# apollo510 register map
Vendor: Ambiq Micro; Series: Apollo; File version: 1.0
CPU: CM55 r1p1, little endian, MPU, FPU, double-precision FPU, DSP, I-cache, D-cache, VTOR, ITCM, DTCM, 4 interrupt priority bits, 0 interrupts, 8 SAU regions
Registers are 32-bit, read-write, reset 0x0 unless marked. A register's access mark holds for its fields unless they carry their own. Offsets are from the block's base; [hi:lo] are bit positions; {n}, {i} and the like mark numbered series; 'fields as' and 'values as' point back to an identical list.

## SDIO0 (part 2 of 2) — SDIO Control Registers
Base 0x40070000
Same registers: SDIO1 0x40071000
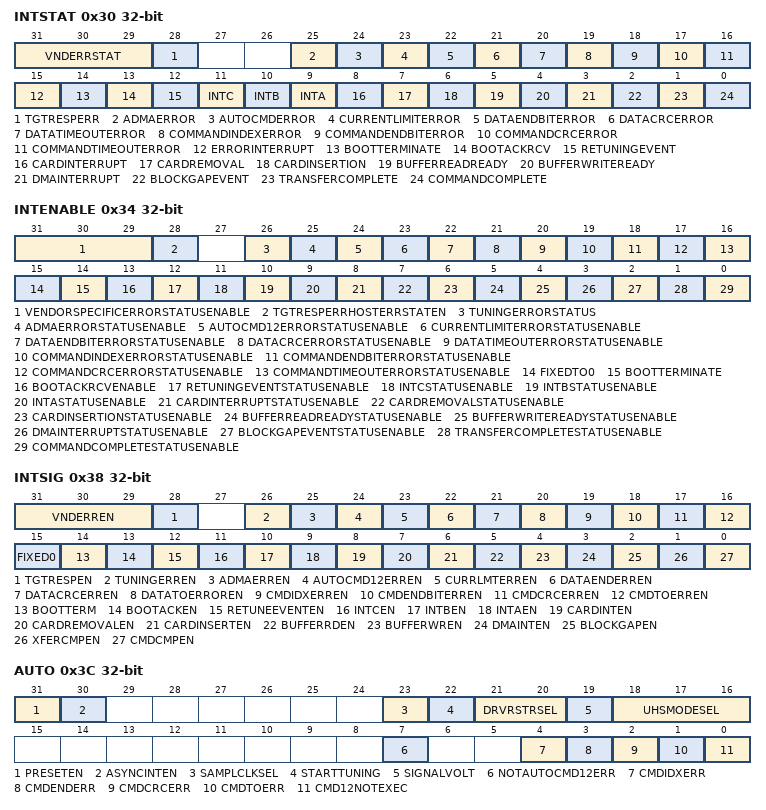
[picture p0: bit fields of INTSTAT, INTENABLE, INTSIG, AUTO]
0x30 INTSTAT — Interrupt enable
  [31:29] VNDERRSTAT — Vendor specific error status.
    1=READY; 0=NOTREADY
  [28] TGTRESPERR — Occurs when detecting error in aximst_bresp or aximst_rresp
    0=NOERROR; 1=ERROR
  [25] ADMAERROR — This bit is set when the Host Controller detects errors during ADMA based data transfer. The state of the ADMA at an error occurrence is saved in the ADMA Error Status Register.
    1=ERROR; 0=NOERROR
  [24] AUTOCMDERROR — Auto CMD12 and Auto CMD23 use this error status. This bit is set when detecting that one of the bits D00-D04 in Auto CMD Error Status register has changed from 0 to 1. In case of Auto CMD12, this bit is set to 1, not only when the errors in Auto CMD12 occur but also when Auto CMD12 is not executed due to the previous command error.
    0=NOERROR; 1=ERROR
  [23] CURRENTLIMITERROR — By setting the SD Bus Power bit in the Power Control Register, the HC is requested to supply power for the SD Bus. If the HC supports the Current Limit Function, it can be protected from an Illegal card by stopping power supply to the card in which case this bit indicates a failure status. Reading 1 means the HC is not supplying power to SD card due to some failure. Reading 0 means that the HC is supplying power and no error has occurred. This bit shall always set to be 0, if the HC does not support this function.
    0=NOERROR; 1=ERROR (Power Fail)
  [22] DATAENDBITERROR — Occurs when detecting 0 at the end bit position of read data which uses the DAT line or the end bit position of the CRC status.
    0=NOERROR; 1=ERROR
  [21] DATACRCERROR — Occurs when detecting CRC error when transferring read data which uses the DAT line or when detecting the Write CRC Status having a value of other than 0.
    0=NOERROR; 1=ERROR
  [20] DATATIMEOUTERROR — Occurs when detecting one of following timeout conditions. 1. Busy Timeout for R1b, R5b type. 2. Busy Timeout after Write CRC status 3. Write CRC status Timeout 4. Read Data Timeout
    0=NOERROR; 1=ERROR (Timeout)
  [19] COMMANDINDEXERROR — Occurs if a Command Index error occurs in the Command Response.
    0=NOERROR; 1=ERROR
  [18] COMMANDENDBITERROR — Occurs only if the no response is returned within 64 SDCLK cycles from the end bit of the command. If the HC detects a CMD line conflict, in which case Command CRC Error shall also be set. This bit shall be set without waiting for 64 SDCLK cycles because the command will be aborted by the HC.
    0=NOERROR; 1=ERROR (Timeout)
  [17] COMMANDCRCERROR — Occurs when detecting that the end bit of a command response is 0.
    0=NOERROR; 1=ERROR (End Bit Error Generated)
  [16] COMMANDTIMEOUTERROR — Command CRC Error is generated in two cases. 1. If a response is returned and the Command Time-out Error is set to 0, this bit is set to 1 when detecting a CRT error in the command response 2. The HC detects a CMD line conflict by monitoring the CMD line when a command is issued. If the HC drives the CMD line to 1 level, but detects 0 level on the CMD line at the next SDCLK edge, then the HC shall abort the command (Stop driving CMD line) and set this bit to 1. The Command Timeout Error shall also be set to 1 to distinguish CMD line conflict.
    0=NOERROR; 1=ERROR (CRC Error Generated)
  [15] ERRORINTERRUPT — If any of the bits in the Error Interrupt Status Register are set, then this bit is set. Therefore the HD can test for an error by checking this bit first.
    0=NOERROR; 1=ERROR
  [14] BOOTTERMINATE — Interrupt This status is set if the boot operation get terminated
    0=OK (Boot operation is not terminated.); 1=BOOTTERM (Boot operation is terminated)
  [13] BOOTACKRCV — This status is set if the boot acknowledge is received from device.
    0=NOACK (Boot ack is not received.); 1=ACK (Boot ack is received.)
  [12] RETUNINGEVENT — This status is set if Re-Tuning Request in the Present State register changes from 0 to 1. Host Controller requests Host Driver to perform re-tuning for next data transfer. Current data transfer (not large block count) can be completed without re-tuning.
    1=RETUNE (ReTuning should be performed); 0=NORETUNE (ReTuning is not required)
  [11] INTC — This status is set if INT_C is enabled and INT_C# pin is in low level. Writing this bit to 1 does not clear this bit. It is cleared by resetting the INT_C interrupt factor
  [10] INTB — This status is set if INT_B is enabled and INT_B# pin is in low level. Writing this bit to 1 does not clear this bit. It is cleared by resetting the INT_B interrupt factor
  [9] INTA — This status is set if INT_A is enabled and INT_A# pin is in low level. Writing this bit to 1 does not clear this bit. It is cleared by resetting the INT_A interrupt factor
  [8] CARDINTERRUPT — Writing this bit to 1 does not clear this bit. It is cleared by resetting the SD card interrupt factor. In 1-bit mode, the HC shall detect the Card Interrupt without SD Clock to support wakeup. In 4-bit mode, the card interrupt signal is sampled during the interrupt cycle, so there are some sample delays between the interrupt signal from the card and the interrupt to the Host system. when this status has been set and the HD needs to start this interrupt service, Card Interrupt Status Enable in the Normal Interrupt Status register shall be set to 0 in order to clear the card interrupt statuses latched in the HC and stop driving the Host System. After completion of the card interrupt service (the reset factor in the SD card and the interrupt signal may not be asserted), set Card Interrupt Status Enable to 1 and start sampling the interrupt signal again. Interrupt detected by DAT[1] is supported when there is a card per slot. In case of shared bus, interrupt pins are used to detect interrupts. If 000b is set to Interrupt Pin Select in the Shared Bus Control register, this status is effective. Non-zero value is set to Interrupt Pin Select, INT_A, INT_B or INT_C is then used to device interrupts.
    0=NOINT (No Card Interrupt); 1=INT (Generate Card Interrupt)
  [7] CARDREMOVAL — This status is set if the Card Inserted in the Present State register changes from 1 to 0. When the HD writes this bit to 1 to clear this status the status of the Card Inserted in the Present State register should be confirmed. Because the card detect may possibly be changed when the HD clear this bit an Interrupt event may not be generated.
    0=STABLE (Card State Stable or Debouncing); 1=REMOVED (Card Removed)
  [6] CARDINSERTION — This status is set if the Card Inserted in the Present State register changes from 0 to 1. When the HD writes this bit to 1 to clear this status the status of the Card Inserted in the Present State register should be confirmed. Because the card detect may possibly be changed when the HD clear this bit an Interrupt event may not be generated.
    0=STABLE (Card State Stable or Debouncing); 1=INSERTED (Card Inserted)
  [5] BUFFERREADREADY — This status is set if the Buffer Read Enable changes from 0 to 1. Buffer Read Ready is set to 1 for every CMD19 execution in tuning procedure.
    0=NOREADY (Not Ready to read Buffer.); 1=READY (Ready to read Buffer.)
  [4] BUFFERWRITEREADY — This status is set if the Buffer Write Enable changes from 0 to 1.
    0=NOTREADY (Not Ready to Write Buffer.); 1=READY (Ready to Write Buffer.)
  [3] DMAINTERRUPT — This status is set if the HC detects the Host DMA Buffer Boundary in the Block Size regiser.
    0=NOINT (No DMA Interrupt); 1=INT (DMA Interrupt is Generated)
  [2] BLOCKGAPEVENT — If the Stop At Block Gap Request in the Block Gap Control Register is set, this bit is set. Read Transaction: This bit is set at the falling edge of the DAT Line Active Status (When the transaction is stopped at SD Bus timing. The Read Wait must be supported inorder to use this function). Write Transaction: This bit is set at the falling edge of Write Transfer Active Status (After getting CRC status at SD Bus timing).
    0=NOEVENT (No Block Gap Event); 1=STOPPED (Transaction stopped at Block Gap)
  [1] TRANSFERCOMPLETE — This bit is set when a read / write transaction is completed. Read Transaction: This bit is set at the falling edge of Read Transfer Active Status. There are two cases in which the Interrupt is generated. The first is when a data transfer is completed as specified by data length (After the last data has been read to the Host System). The second is when data has stopped at the block gap and completed the data transfer by setting the Stop At Block Gap Request in the Block Gap Control Register (After valid data has been read to the Host System). Write Transaction: This bit is set at the falling edge of the DAT Line Active Status. There are two cases in which the Interrupt is generated. The first is when the last data is written to the card as specified by data length and Busy signal is released. The second is when data transfers are stopped at the block gap by setting Stop At Block Gap Request in the Block Gap Control Register and data transfers completed. (After valid data is written to the SD card and the busy signal is released). Note: Transfer Complete has higher priority than Data Time-out Error. If both bits are set to 1, the data transfer can be considered complete Note: While performing tuning procedure (Execute Tuning is set to 1), Transfer Complete is not set to 1
    0=NODATA (No Data Transfer Complete); 1=COMPLETE (Data Transfer Complete)
  [0] COMMANDCOMPLETE — This bit is set when we get the end bit of the command response (Except Auto CMD12 and Auto CMD23) Note: Command Time-out Error has higher priority than Command Complete. If both are set to 1, it can be considered that the response was not received correctly.
    0=NOCMP (No Command Complete); 1=CMDCMP (Command Complete)
0x34 INTENABLE — Normal interrupt status enable
  [31:29] VENDORSPECIFICERRORSTATUSENABLE
  [28] TGTRESPERRHOSTERRSTATEN
  [26] TUNINGERRORSTATUS — enable
  [25] ADMAERRORSTATUSENABLE
  [24] AUTOCMD12ERRORSTATUSENABLE
  [23] CURRENTLIMITERRORSTATUSENABLE
  [22] DATAENDBITERRORSTATUSENABLE
  [21] DATACRCERRORSTATUSENABLE
  [20] DATATIMEOUTERRORSTATUSENABLE
  [19] COMMANDINDEXERRORSTATUSENABLE
  [18] COMMANDENDBITERRORSTATUSENABLE
  [17] COMMANDCRCERRORSTATUSENABLE
  [16] COMMANDTIMEOUTERRORSTATUSENABLE
  [15] FIXEDTO0 — The HC shall control error Interrupts using the Error Interrupt Status Enable register.
  [14] BOOTTERMINATE — Boot is terminated?
  [13] BOOTACKRCVENABLE — Interrupt
  [12] RETUNINGEVENTSTATUSENABLE — Interrupt
  [11] INTCSTATUSENABLE — If this bit is set to 0, the Host Controller shall clear the interrupt request to the System. The Host Driver may clear this bit before servicing the INT_C and may set this bit again after all interrupt requests to INT_C pin are cleared to prevent inadvertent interrupts. Interrupt enable
  [10] INTBSTATUSENABLE — If this bit is set to 0, the Host Controller shall clear the interrupt request to the System. The Host Driver may clear this bit before servicing the INT_B and may set this bit again after all interrupt requests to INT_B pin are cleared to prevent inadvertent interrupts.
  [9] INTASTATUSENABLE — If this bit is set to 0, the Host Controller shall clear the interrupt request to the System. The Host Driver may clear this bit before servicing the INT_A and may set this bit again after all interrupt requests to INT_A pin are cleared to prevent inadvertent interrupts.
  [8] CARDINTERRUPTSTATUSENABLE — If this bit is set to 0, the HC shall clear Interrupt request to the System. The Card Interrupt detection is stopped when this bit is cleared and restarted when this bit is set to 1. The HD may clear the Card Interrupt Status Enable before servicing the Card Interrupt and may set this bit again after all Interrupt requests from the card are cleared to prevent inadvertent Interrupts.
  [7] CARDREMOVALSTATUSENABLE — Description
  [6] CARDINSERTIONSTATUSENABLE — Description
  [5] BUFFERREADREADYSTATUSENABLE — Description
  [4] BUFFERWRITEREADYSTATUSENABLE — Description
  [3] DMAINTERRUPTSTATUSENABLE — Description
  [2] BLOCKGAPEVENTSTATUSENABLE — Description
  [1] TRANSFERCOMPLETESTATUSENABLE — Description
  [0] COMMANDCOMPLETESTATUSENABLE — Description
0x38 INTSIG — Normal interrupt signal enable
  [31:29] VNDERREN — FIXME - Bitfield description needed here.
  [28] TGTRESPEN — Interrupt
    0=MASKED; 1=ENABLED
  [26] TUNINGERREN
    0=MASKED; 1=ENABLED
  [25] ADMAERREN
    0=MASKED; 1=ENABLED
  [24] AUTOCMD12ERREN
    0=MASKED; 1=ENABLED
  [23] CURRLMTERREN
    0=MASKED; 1=ENABLED
  [22] DATAENDERREN
    0=MASKED; 1=ENABLED
  [21] DATACRCERREN
    0=MASKED; 1=ENABLED
  [20] DATATOERROREN
    0=MASKED; 1=ENABLED
  [19] CMDIDXERREN
    0=MASKED; 1=ENABLED
  [18] CMDENDBITERREN
    0=MASKED; 1=ENABLED
  [17] CMDCRCERREN
    0=MASKED; 1=ENABLED
  [16] CMDTOERREN
    0=MASKED; 1=ENABLED
  [15] FIXED0 — Fixed to 0. The HD shall control error Interrupts using the Error Interrupt Signal Enable register.
    0=MASKED; 1=ENABLED
  [14] BOOTTERM — Boot terminate interrupt signal enable
    0=MASKED; 1=ENABLED
  [13] BOOTACKEN — Interrupt
    0=MASKED; 1=ENABLED
  [12] RETUNEEVENTEN — Interrupt signal enable
    0=MASKED; 1=ENABLED
  [11] INTCEN — Interrupt
    0=MASKED; 1=ENABLED
  [10] INTBEN — Interrupt
    0=MASKED; 1=ENABLED
  [9] INTAEN — Interrupt
    0=MASKED; 1=ENABLED
  [8] CARDINTEN — Interrupt
    0=MASKED; 1=ENABLED
  [7] CARDREMOVALEN — Interrupt
    0=MASKED; 1=ENABLED
  [6] CARDINSERTEN — Interrupt
    0=MASKED; 1=ENABLED
  [5] BUFFERRDEN — Interrupt
    0=MASKED; 1=ENABLED
  [4] BUFFERWREN — Interrupt
    0=MASKED; 1=ENABLED
  [3] DMAINTEN — Interrupt
    0=MASKED; 1=ENABLED
  [2] BLOCKGAPEN — Interrupt
    0=MASKED; 1=ENABLED
  [1] XFERCMPEN — Interrupt
    0=MASKED; 1=ENABLED
  [0] CMDCMPEN — Interrupt
    0=MASKED; 1=ENABLED
0x3C AUTO — Auto CMD error status
  [31] PRESETEN — Host Controller Version 3.00 supports this bit. As the operating SDCLK frequency and I/O driver strength depend on the Host System implementation, it is difficult to determine these parameters in the Standard Host Driver. When Preset Value Enable is set to automatic. This bit enables the functions defined in the Preset Value registers. If this bit is set to 0, SDCLK Frequency Select, Clock Generator Select in the Clock Control register and Driver Strength Select in Host Control 2 register are set by Host Driver. If this bit is set to 1, SDCLK Frequency Select, Clock Generator Select in the Clock Control register and Driver Strength Select in Host Control 2 register are set by Host Controller as specified in the Preset Value registers.
    1=AUTOEN (Automatic Selection by Preset Value are Enabled); 0=HOSTCTRL (SDCLK and Driver Strength are controlled by Host Driver)
  [30] ASYNCINTEN — This bit can be set to 1 if a card support asynchronous interrupt and Asynchronous Interrupt Support is set to 1 in the Capabilities register. Asynchronous interrupt is effective when DAT[1] interrupt is used in 4-bit SD mode (and zero is set to Interrupt Pin Select in the Shared Bus Control register). If this bit is set to 1, the Host Driver can stop the SDCLK during asynchronous interrupt period to save power. During this period, the Host Controller continues to deliver Card Interrupt to the host when it is asserted by the Card.
    1=ENABLED; 0=DISABLED
  [23] SAMPLCLKSEL — This bit is set by tuning procedure when Execute Tuning is cleared. Writing 1 to this bit is meaningless and ignored. Setting 1 means that tuning is completed successfully and setting 0 means that tuning is failed. Host Controller uses this bit to select sampling clock to receive CMD and DAT. This bit is cleared by writing 0. Change of this bit is not allowed while the Host Controller is receiving response or a read data block.
    1=TUNEDCLK (Tuned clock is used to sample data); 0=FIXEDCLK (Fixed clock is used to sample data)
  [22] STARTTUNING — This bit is set to 1 to start tuning procedure and automatically cleared when tuning procedure is completed. The result of tuning is indicated to Sampling Clock Select. Tuning procedure is aborted by writing 0 for more detail about tuning procedure.
    1=TUNESTART (Execute Tuning,); 0=TUNECMP (Not Tuned or Tuning Completed)
  [21:20] DRVRSTRSEL — Host Controller output driver in 1.8V signaling is selected by this bit. In 3.3V signaling, this field is not effective. This field can be set depends on Driver Type A, C and D support bits in the Capabilities register. This bit depends on setting of Preset Value Enable. If Preset Value Enable = 0, this field is set by Host Driver. If Preset Value Enable = 1, this field is automatically set by a value specified in the one of Preset Value registers.
    0=DRVRB (Driver Type B is Selected (Default)); 1=DRVRA (Driver Type A is Selected); 2=DRVRC (Driver Type C is Selected); 3=DRVRD (Driver Type D is Selected)
  [19] SIGNALVOLT — This bit controls voltage regulator for I/O cell. 3.3V is supplied to the card regardless of signaling voltage. Setting this bit from 0 to 1 starts changing signal voltage from 3.3V to 1.8V. 1.8V regulator output shall be stable within 5ms. Host Controller clears this bit if switching to 1.8V signaling fails. Clearing this bit from 1 to 0 starts changing signal voltage from 1.8V to 3.3V. 3.3V regulator output shall be stable within 5ms. Host Driver can set this bit to 1 when Host Controller supports 1.8V signaling (One of support bits is set to 1: SDR50, SDR104 or DDR50 in the Capabilities register) and the card or device supports UHS-I
    1=1_8V (1.8V Signaling); 0=3_3V (3.3V Signaling)
  [18:16] UHSMODESEL — This field is used to select one of UHS-I modes and effective when 1.8V Signaling Enable is set to 1. If Preset Value Enable in the Host Control 2 register is set to 1, Host Controller sets SDCLK Frequency Select, Clock Generator Select in the Clock Control register and Driver Strength Select according to Preset Value registers. In this case, one of preset value registers is selected by this field. Host Driver needs to reset SD Clock Enable before changing this field to avoid generating clock glitch. After setting this field, Host Driver sets SD Clock Enable again. When SDR50, SDR104 or DDR50 is selected for SDIO card, interrupt detection at the block gap shall not be used. Read Wait timing is changed for these modes. Refer to the SDIO Specification Version 3.00 for more detail.
    0=SDR12 (UHS-I mode SDR12); 1=SDR25 (UHS-I mode SDR25); 2=SDR50 (UHS-I mode SDR50); 3=SDR104 (UHS-I mode SDR104); 4=DDR50 (UHS-I mode DDR50)
  [7] NOTAUTOCMD12ERR — Setting this bit to 1 means CMD_wo_DAT is not executed due to an Auto CMD12 error (D04 - D01) in this register. This bit is set to 0 when Auto CMD Error is generated by Auto CMD23
    0=NOERROR; 1=ERROR (Not Issued)
  [4] CMDIDXERR — Occurs if the Command Index error occurs in response to a command.
    0=NOERROR; 1=ERROR
  [3] CMDENDERR — Occurs when detecting that the end bit of command response is 0.
    0=NOERROR; 1=ERROR (End Bit Error Generated)
  [2] CMDCRCERR — Occurs when detecting a CRC error in the command response.
    0=NOERROR; 1=ERROR (CRC Error Generated)
  [1] CMDTOERR — Occurs if the no response is returned within 64 SDCLK cycles from the end bit of the command. If this bit is set to 1, the other error status bits (D04 - D02) are meaningless.
    0=NOERROR; 1=ERROR (Timeout)
  [0] CMD12NOTEXEC — If memory multiple block data transfer is not started due to command error, this bit is not set because it is not necessary to issue Auto CMD12. Setting this bit to 1 means the HC cannot issue Auto CMD12 to stop memory multiple block transfer due to some error. If this bit is set to 1, other error status bits (D04 - D01) are meaningless. This bit is set to 0 when Auto CMD Error is generated by Auto CMD23
    0=EXECUTED; 1=NOTEXECUTED
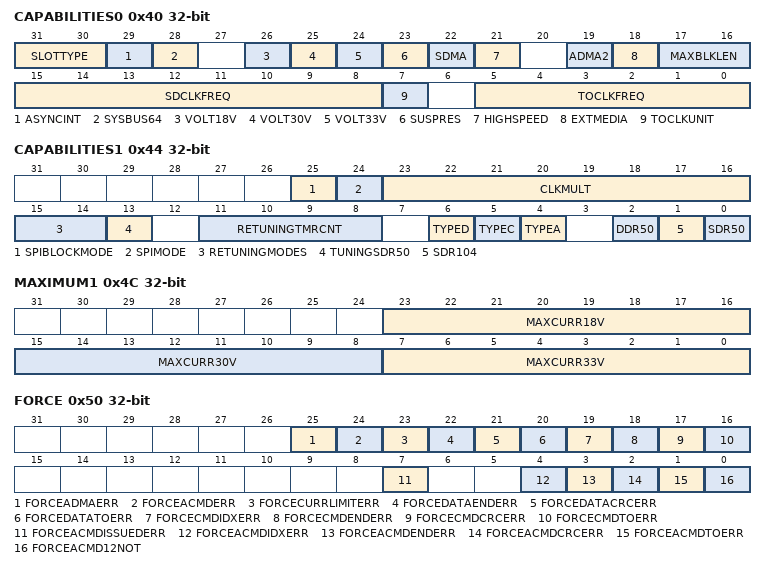
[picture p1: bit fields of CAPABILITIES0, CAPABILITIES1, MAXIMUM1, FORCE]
0x40 CAPABILITIES0 — Capabilities
  [31:30] SLOTTYPE — This field indicates usage of a slot by a specific Host System. (A host controller register set is defined per slot.) Embedded slot for one device (01b) means that only one non-removable device is connected to a SD bus slot. Shared Bus Slot (10b) can be set if Host Controller supports Shared Bus Control register. The Standard Host Driver controls only a removable card or one embedded device is connected to a SD bus slot. If a slot is configured for shared bus (10b), the Standard Host Driver does not control embedded devices connected to a shared bus. Shared bus slot is controlled by a specific host driver developed by a Host System.
    0=REMOVABLE (Removable card slot); 1=EMBEDDED (Embedded Slot for One Device); 2=SHARED (Shared Bus Slot)
  [29] ASYNCINT — Refer to SDIO Specification Version 3.00 about asynchronous interrupt.
    1=SUPPORTED (Asynchronous Interrupt Supported); 0=NOTSUPPORTED (Asynchronous Interrupt Not Supported)
  [28] SYSBUS64
    1=SUPPORTED (Supports 64 bit system address); 0=NOTSUPPORTED (Does not support 64 bit system address)
  [26] VOLT18V — Voltage support 1.8v
    0=NOTSUPPORTED (1.8 V Not Supported); 1=SUPPORTED (1.8 V Supported)
  [25] VOLT30V — Voltage support 3.0v
    0=NOTSUPPORTED (3.0 V Not Supported); 1=SUPPORTED (3.0 V Supported)
  [24] VOLT33V
    0=NOTSUPPORTED (3.3 V Not Supported); 1=SUPPORTED (3.3 V Supported)
  [23] SUSPRES — This bit indicates whether the HC supports Suspend / Resume functionality. If this bit is 0, the Suspend and Resume mechanism are not supported and the HD shall not issue either Suspend / Resume commands.
    0=NOTSUPPORTED (Suspend / Resume Not Supported); 1=SUPPORTED (Suspend / Resume Supported)
  [22] SDMA — This bit indicates whether the HC is capable of using DMA to transfer data between system memory and the HC directly.
    0=NOTSUPPORTED (SDMA Not Supported); 1=SUPPORTED (SDMA Supported.)
  [21] HIGHSPEED — This bit indicates whether the HC and the Host System support High Speed mode and they can supply SD Clock frequency from 25Mhz to 50 Mhz (for SD)/ 20MHz to 52MHz (for MMC).
    0=NOTSUPPORTED (High Speed Not Supported); 1=SUPPORTED (High Speed Supported)
  [19] ADMA2
    1=SUPPORTED (ADMA2 support.); 0=NOTSUPPORTED (ADMA2 not support)
  [18] EXTMEDIA — This bit indicates whether the Host Controller is capable of using 8-bit bus width mode. This bit is not effective when Slot Type is set to 10b. In this case, refer to Bus Width Preset in the Shared Bus resister. Supported
    1=SUPPORTED (Extended Media Bus Supported); 0=NOTSUPPORTED (Extended Media Bus not supported)
  [17:16] MAXBLKLEN — This value indicates the maximum block size that the HD can read and write to the buffer in the HC. The buffer shall transfer this block size without wait cycles. Three sizes can be defined as indicated below.
    0=512 byte; 1=1024 byte; 2=2048 byte; 3=4096 byte
  [15:8] SDCLKFREQ — 6-bit Base Clock Frequency This mode is supported by the Host Controller Version 1.00 and 2.00. Upper 2-bit is not effective and always 0. Unit values are 1MHz. The supported clock range is 10MHz to 63MHz. 11xx xxxxb Not supported 0011 1111b 63MHz 0000 0010b 2MHz 0000 0001b 1MHz 0000 0000b Get information via another method (2) 8-bit Base Clock Frequency This mode is supported by the Host Controller Version 3.00.Unit values are 1MHz. The supported clock range is 10MHz to 255MHz. FFh 255MHz 02h 2MHz 01h 1MHz 00h Get information via another method If the real frequency is 16.5MHz, the lager value shall be set 0001 0001b (17MHz) because the Host Driver use this value to calculate the clock divider value (Refer to the SDCLK Frequency Select in the Clock Control register.) and it shall not exceed upper limit of the SD Clock frequency. If these bits are all 0, the Host System has to get information via another method. Some example frequency values are enumerated below.
    255=255MHZ (2) 8-bit base clock frequency supports frequencies 10MHz-255MHz.); 63=63MHZ (1) 6-bit base clock frequency supports frequencies 10MHz-63MHz. 2) 8-bit base clock frequency supports frequencies 10MHz-255MHz.); 2=2MHZ (1) 6-bit base clock frequency supports frequencies 10MHz-63MHz. 2) 8-bit base clock frequency supports frequencies 10MHz-255MHz.); 1=1MHZ (1) 6-bit base clock frequency supports frequencies 10MHz-63MHz. 2) 8-bit base clock frequency supports frequencies 10MHz-255MHz.); 0=OTHER (Get information via another method)
  [7] TOCLKUNIT — This bit shows the unit of base clock frequency used to detect Data Timeout Error.
    0=KHZ; 1=MHZ
  [5:0] TOCLKFREQ — This bit shows the base clock frequency used to detect Data Timeout Error. Not 0 - 1Khz to 63Khz or 1Mhz to 63Mhz Note: The Host System shall support at least one of these voltages above. The HD sets the SD Bus Voltage Select in Power Control register according to these support bits. If multiple voltages are supported, select the usable lower voltage by comparing the OCR value from the card. These registers indicate maximum current capability for each voltage. The value is meaningful if Voltage Support is set in the Capabilities register.
    1=1KHZMHZ (1KHZ or 1MHZ); 2=2KHZMHZ (2KHZ or 2MHZ); 63=63KHZMHZ (63KHZ or 63MHZ); 0=OTHER (Get Information via another method.)
0x44 CAPABILITIES1 — Capabilities
  [25] SPIBLOCKMODE
    0=NOTSUPPORTED; 1=SUPPORTED
  [24] SPIMODE
    0=NOTSUPPORTED; 1=SUPPORTED
  [23:16] CLKMULT — This field indicates clock multiplier value of programmable clock generator. Refer to Clock Control register. Setting 00h means that Host Controller does not support programmable clock generator. The multiplier is (CLKMULT+1).
    255=MULTX256 (Clock Multiplier M = 256); 2=MULTX3 (Clock Multiplier M = 3); 1=MULTX2 (Clock Multiplier M = 2); 0=NOTSUPPORTED (Clock Multiplier is Not Supported)
  [15:14] RETUNINGMODES — This field defines the re-tuning capability of a Host Controller and how to manage the data transfer length and a Re-Tuning Timer by the Host Driver There are two re-tuning timings: Re-Tuning Request and expiration of a Re-Tuning Timer. By receiving either timing, the Host Driver executes the re-tuning procedure just before a next command issue
    0=MODE1; 1=MODE2; 2=MODE3; 3=NOTSUPPORTED (Clock Multiplier is not supported.)
  [13] TUNINGSDR50 — If this bit is set to 1, this Host Controller requires tuning to operate SDR50. (Tuning is always required to operate SDR104.)
    1=TUNINGREQD (SDR50 requires tuning); 0=NOTUNINGREQD (SDR50 does not require tuning)
  [11:8] RETUNINGTMRCNT — This field indicates an initial value of the Re-Tuning Timer for Re-Tuning Mode 1 to 3. 0h - Get information via other source.
    0=OTHER (0h Get information via other source.); 1=1SEC (1 seconds); 2=2SEC (2 seconds); 3=4SEC (4 seconds); 4=8S (8 seconds); 5=16S (16 seconds); 6=32S (32 seconds); 7=64S (64 seconds); 8=128S (128 seconds); 9=256S (256 seconds); 10=512S (512 seconds); 11=1024S (1024 seconds)
  [6] TYPED — Reserved This bit indicates support of Driver Type D for 1.8 Signaling.
    1=SUPPORTED (Driver Type D is Supported); 0=NOTSUPPORTED (Driver Type D is Not Supported)
  [5] TYPEC — This bit indicates support of Driver Type C for 1.8 Signaling.
    1=SUPPORTED (Driver Type C is Supported); 0=NOTSUPPORTED (Driver Type C is Not Supported)
  [4] TYPEA — This bit indicates support of Driver Type A for 1.8 Signaling.
    1=SUPPORTED (Driver Type A is Supported); 0=NOTSUPPORTED (Driver Type A is Not Supported)
  [2] DDR50 — FIXME - Bitfield description needed here.
    1=SUPPORTED (DDR50 is Supported); 0=NOTSUPPORTED (DDR50 is Not Supported)
  [1] SDR104 — 1- SDR104 is Supported
    1=SUPPORTED (SDR104 is Not Supported); 0=NOTSUPPORTED (SDR104 is Not Supported)
  [0] SDR50 — 1- SDR50 is Supported
    1=SUPPORTED (SDR50 is Not Supported); 0=NOTSUPPORTED (SDR50 is Not Supported)
0x48 MAXIMUM0 — Maximum current capabilities
  [31:0] ALLBITSRSVD — The entire 32-bits of this register are reserved, do not read or write.
0x4C MAXIMUM1 — Maximum current capabilities
  [all] fields
    255=1020mA = 255 * 4mA; 1=4mA (1020mA, 1 * 4mA)
  [23:16] MAXCURR18V — Maximum Current for 1.8V. The current value is specified as MAXCURR18V * 4mA. Some example enums follow:
  [15:8] MAXCURR30V — Maximum Current for 3.0V. The current value is specified as MAXCURR30V * 4mA. Some example enums follow:
  [7:0] MAXCURR33V — Maximum Current for 3.3V. The current value is specified as MAXCURR33V * 4mA. Some example enums follow:
0x50 FORCE — Force event register for error interrupt status
  [25] FORCEADMAERR — Force event for ADMA error
    1=INT (Interrupt is generated); 0=NOINT (No interrupt)
  [24] FORCEACMDERR — Force Event for Auto CMD Error
    1=INT (Interrupt is generated); 0=NOINT (No interrupt)
  [23] FORCECURRLIMITERR — Force Event for Current Limit Error
    1=INT (Interrupt is generated); 0=NOINT (No interrupt)
  [22] FORCEDATAENDERR — Force Event for Data End Bit Error
    1=INT (Interrupt is generated); 0=NOINT (No interrupt)
  [21] FORCEDATACRCERR — Force Event for Data CRC Error
    1=INT (Interrupt is generated); 0=NOINT (No interrupt)
  [20] FORCEDATATOERR — Force Event for Data Timeout Error
    1=INT (Interrupt is generated); 0=NOINT (No interrupt)
  [19] FORCECMDIDXERR — Force Event for Command Index Error
    1=INT (Interrupt is generated); 0=NOINT (No interrupt)
  [18] FORCECMDENDERR — Force Event for Command End Bit Error
    1=INT (Interrupt is generated); 0=NOINT (No interrupt)
  [17] FORCECMDCRCERR — Force Event for Command CRC Error
    1=INT (Interrupt is generated); 0=NOINT (No interrupt)
  [16] FORCECMDTOERR — Force Event for Command Timeout Error
    1=INT (Interrupt is generated); 0=NOINT (No interrupt)
  [7] FORCEACMDISSUEDERR — 1 - Interrupt is generated
    1=INT (Interrupt is generated); 0=NOINT (no interrupt)
  [4] FORCEACMDIDXERR
    1=INT (Interrupt is generated); 0=NOINT (no interrupt)
  [3] FORCEACMDENDERR — Description
    1=INT (Interrupt is generated); 0=NOINT (no interrupt)
  [2] FORCEACMDCRCERR — Description
    1=INT (Interrupt is generated); 0=NOINT (no interrupt)
  [1] FORCEACMDTOERR — Description
    1=INT (Interrupt is generated); 0=NOINT (no interrupt)
  [0] FORCEACMD12NOT — Description
    1=INT (Interrupt is generated); 0=NOINT (no interrupt)
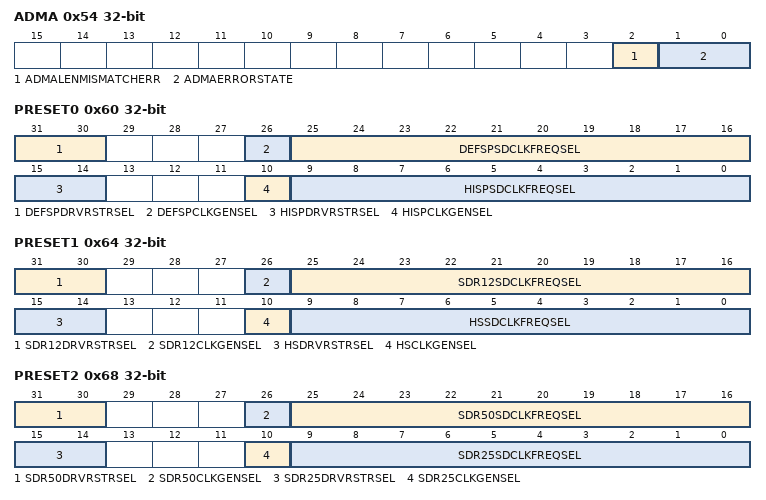
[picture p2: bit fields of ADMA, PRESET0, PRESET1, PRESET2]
0x54 ADMA — ADMA error status
  [2] ADMALENMISMATCHERR — This error occurs in the following 2 cases. While Block Count Enable being set, the total data length specified by the Descriptor table is different from that specified by the Block Count and Block Length. Total data length can not be divided by the block length.
    1=ERROR; 0=NOERROR
  [1:0] ADMAERRORSTATE — This field indicates the state of ADMA when error is occurred during ADMA data transfer. This field never indicates 10 because ADMA never stops in this state. D01 - D00 : ADMA Error State when error occurred Contents of SYS_SDR register
    0=STDMA (ST_STOP (Stop DMA) Points to next of the error descriptor); 1=FETCHDESC (ST_FDS (Fetch Descriptor) Points to the error descriptor); 2=INVALID (Never set this state (Not used)); 3=XFERDATA (ST_TFR (Transfer Data) Points to the next of the error descriptor)
0x58 ADMALOWD — ADMA system address [31:0]
  [31:0] LOWD — This register holds byte address of executing command of the Descriptor table. 32-bit Address Descriptor uses lower 32bit of this register. At the start of ADMA, the Host Driver shall set start address of the Descriptor table. The ADMA increments this register address, which points to next line, when every fetching a Descriptor line. When the ADMA Error Interrupt is generated, this register shall hold valid Descriptor address depending on the ADMA state. The Host Driver shall program Descriptor Table on 32-bit boundary and set 32-bit boundary address to this register. ADMA2 ignores lower 2-bit of this register and assumes it to be 00b. 32-bit Address ADMA Register Value 32bit System Address
0x5C ADMAHIWD — ADMA system address [63:0]
  [31:0] HIWD — This register holds byte address of executing command of the Descriptor table. 32-bit Address Descriptor uses lower 32bit of this register. At the start of ADMA, the Host Driver shall set start address of the Descriptor table. The ADMA increments this register address, which points to next line, when every fetching a Descriptor line. When the ADMA Error Interrupt is generated, this register shall hold valid Descriptor address depending on the ADMA state. The Host Driver shall program Descriptor Table on 32-bit boundary and set 32-bit boundary address to this register. ADMA2 ignores lower 2-bit of this register and assumes it to be 00b. 32-bit Address ADMA Register Value 32bit System Address
0x60 PRESET0 — Preset Value initialization and default speed
  [31:30] DEFSPDRVRSTRSEL — Driver Strength is supported by 1.8V signaling bus speed modes. This field is meaningless for 3.3V signaling.
    3=TYPED (Driver Type D is Selected); 2=TYPEC (Driver Type C is Selected); 1=TYPEA (Driver Type A is Selected); 0=TYPEB (Driver Type B is Selected)
  [26] DEFSPCLKGENSEL — This bit is effective when Host Controller supports programmable clock generator.
    1=PROGCLK (Programmable Clock Generator); 0=HOSTCTLR (Host Controller Ver2.00 Compatible Clock Generator)
  [25:16] DEFSPSDCLKFREQSEL — 10 bit preset value to set SDCLK Frequency Select in the Clock Control Register is described by a host system. When Host Controller supports shared bus, a set of Preset Value registers for each device required and the registers location are duplicated to the offset 06Fh-060h. A set of Preset Value registers can be accessible by selecting Clock Pin Select in the Shared Bus Control register
  [15:14] HISPDRVRSTRSEL — Driver Strength is supported by 1.8V signaling bus speed modes. This field is meaningless for 3.3V signaling.
    values as DEFSPDRVRSTRSEL
  [10] HISPCLKGENSEL — This bit is effective when Host Controller supports programmable clock generator.
    values as DEFSPCLKGENSEL
  [9:0] HISPSDCLKFREQSEL — 10 bit preset value to set SDCLK Frequency Select in the Clock Control Register is described by a host system. When Host Controller supports shared bus, a set of Preset Value registers for each device required and the registers location are duplicated to the offset 06Fh-060h. A set of Preset Value registers can be accessible by selecting Clock Pin Select in the Shared Bus Control register
0x64 PRESET1 — Preset Value for high speed and SDR12
  [31:30] SDR12DRVRSTRSEL — Driver Strength is supported by 1.8V signaling bus speed modes. This field is meaningless for 3.3V signaling.
    values as PRESET0.DEFSPDRVRSTRSEL
  [26] SDR12CLKGENSEL — This bit is effective when Host Controller supports programmable clock generator.
    values as PRESET0.DEFSPCLKGENSEL
  [25:16] SDR12SDCLKFREQSEL — 10 bit preset value to set SDCLK Frequency Select in the Clock Control Register is described by a host system. When Host Controller supports shared bus, a set of Preset Value registers for each device required and the registers location are duplicated to the offset 06Fh-060h. A set of Preset Value registers can be accessible by selecting Clock Pin Select in the Shared Bus Control register
  [15:14] HSDRVRSTRSEL — Driver Strength is supported by 1.8V signaling bus speed modes. This field is meaningless for 3.3V signaling.
    values as PRESET0.DEFSPDRVRSTRSEL
  [10] HSCLKGENSEL — This bit is effective when Host Controller supports programmable clock generator.
    values as PRESET0.DEFSPCLKGENSEL
  [9:0] HSSDCLKFREQSEL — 10 bit preset value to set SDCLK Frequency Select in the Clock Control Register is described by a host system. When Host Controller supports shared bus, a set of Preset Value registers for each device required and the registers location are duplicated to the offset 06Fh-060h. A set of Preset Value registers can be accessible by selecting Clock Pin Select in the Shared Bus Control register
0x68 PRESET2 — Preset Value for SDR25 and SDR50
  [31:30] SDR50DRVRSTRSEL — Driver Strength is supported by 1.8V signaling bus speed modes. This field is meaningless for 3.3V signaling.
    values as PRESET0.DEFSPDRVRSTRSEL
  [26] SDR50CLKGENSEL — This bit is effective when Host Controller supports programmable clock generator.
    values as PRESET0.DEFSPCLKGENSEL
  [25:16] SDR50SDCLKFREQSEL — 10 bit preset value to set SDCLK Frequency Select in the Clock Control Register is described by a host system. When Host Controller supports shared bus, a set of Preset Value registers for each device required and the registers location are duplicated to the offset 06Fh-060h. A set of Preset Value registers can be accessible by selecting Clock Pin Select in the Shared Bus Control register
  [15:14] SDR25DRVRSTRSEL — Driver Strength is supported by 1.8V signaling bus speed modes. This field is meaningless for 3.3V signaling.
    values as PRESET0.DEFSPDRVRSTRSEL
  [10] SDR25CLKGENSEL — This bit is effective when Host Controller supports programmable clock generator.
    values as PRESET0.DEFSPCLKGENSEL
  [9:0] SDR25SDCLKFREQSEL — 10 bit preset value to set SDCLK Frequency Select in the Clock Control Register is described by a host system. When Host Controller supports shared bus, a set of Preset Value registers for each device required and the registers location are duplicated to the offset 06Fh-060h. A set of Preset Value registers can be accessible by selecting Clock Pin Select in the Shared Bus Control register
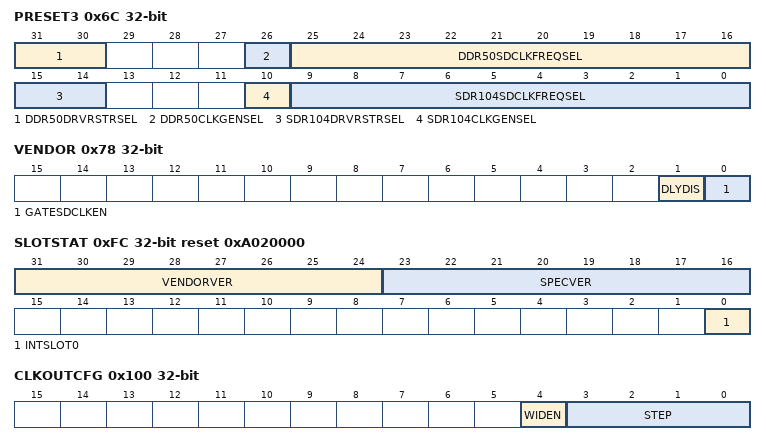
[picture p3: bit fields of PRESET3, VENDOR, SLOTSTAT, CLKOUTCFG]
0x6C PRESET3 — Preset Value for SDR104 and DDR50
  [31:30] DDR50DRVRSTRSEL — Driver Strength is supported by 1.8V signaling bus speed modes. This field is meaningless for 3.3V signaling.
    values as PRESET0.DEFSPDRVRSTRSEL
  [26] DDR50CLKGENSEL — This bit is effective when Host Controller supports programmable clock generator.
    values as PRESET0.DEFSPCLKGENSEL
  [25:16] DDR50SDCLKFREQSEL — 10 bit preset value to set SDCLK Frequency Select in the Clock Control Register is described by a host system. When Host Controller supports shared bus, a set of Preset Value registers for each device required and the registers location are duplicated to the offset 06Fh-060h. A set of Preset Value registers can be accessible by selecting Clock Pin Select in the Shared Bus Control register
  [15:14] SDR104DRVRSTRSEL — Driver Strength is supported by 1.8V signaling bus speed modes. This field is meaningless for 3.3V signaling.
    values as PRESET0.DEFSPDRVRSTRSEL
  [10] SDR104CLKGENSEL — This bit is effective when Host Controller supports programmable clock generator.
    values as PRESET0.DEFSPCLKGENSEL
  [9:0] SDR104SDCLKFREQSEL — 10 bit preset value to set SDCLK Frequency Select in the Clock Control Register is described by a host system. When Host Controller supports shared bus, a set of Preset Value registers for each device required and the registers location are duplicated to the offset 06Fh-060h. A set of Preset Value registers can be accessible by selecting Clock Pin Select in the Shared Bus Control register
0x70 BOOTTOCTRL — Boot Data Timeout control
  [31:0] BOOTDATATO — This value determines the interval by which DAT line time-outs are detected during boot operation for eMMC card. The value is in number of sd clock.
0x78 VENDOR
  [1] DLYDIS — Chicken bit added to enable/disable the rtl fix made to delay the sampling of cmd_in and data_in.
    1=DISABLE (Disable the rtl fix made to delay the sampling of cmd_in and data_in); 0=ENABLE (Enable the rtl fix made to delay the sampling of cmd_in and data_in)
  [0] GATESDCLKEN — If this bit is 0, SD_CLK to card will not be gated automatically, when there is no transfer. If this bit set to 1, SD_CLK to card will be gated automatically,when there is no transfer.
    1=GATE (SD_CLK to card will be gated automatically when there is no transfer.); 0=NOGATE (SD_CLK to card will NOT be gated automatically when there is no transfer.)
0xFC SLOTSTAT reset 0xA020000 — Slot interrupt status
  [31:24] VENDORVER — The Vendor Version Number is set to 0x10 (1.0)
  [23:16] SPECVER — The Host Controller Version Number is set to 0x02 (SD Host Specification Version 3.00).
  [0] INTSLOT0 — This status bit indicates the OR of Interrupt signal and Wakeup signal for slot
0x100 CLKOUTCFG — clkout configure
  [4] WIDEN — narrow or widen the high portion
    1=W (widen); 0=N (narrow)
  [3:0] STEP — tune step
    0=DIS (disable clock duty cycle tuning); 1=1STEP (clock duty cycle tuning with amount of 1 step); {v}={v}STEP (clock duty cycle tuning with amount of {v} steps) (v=2..15)
